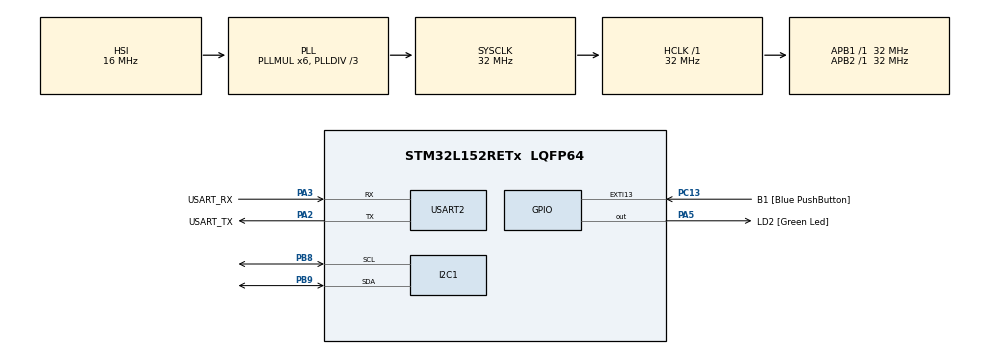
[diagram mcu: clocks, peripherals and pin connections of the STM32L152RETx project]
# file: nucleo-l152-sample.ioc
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Dma.Request0=USART2_RX
Dma.Request1=USART2_TX
Dma.USART2_RX.0.Direction=DMA_PERIPH_TO_MEMORY
Dma.USART2_RX.0.Instance=DMA1_Channel6
Dma.USART2_RX.0.MemDataAlignment=DMA_MDATAALIGN_BYTE
Dma.USART2_RX.0.MemInc=DMA_MINC_ENABLE
Dma.USART2_RX.0.Mode=DMA_NORMAL
Dma.USART2_RX.0.PeriphDataAlignment=DMA_PDATAALIGN_BYTE
Dma.USART2_RX.0.PeriphInc=DMA_PINC_DISABLE
Dma.USART2_RX.0.Priority=DMA_PRIORITY_LOW
Dma.USART2_TX.1.Direction=DMA_MEMORY_TO_PERIPH
Dma.USART2_TX.1.Instance=DMA1_Channel7
Dma.USART2_TX.1.MemDataAlignment=DMA_MDATAALIGN_BYTE
Dma.USART2_TX.1.MemInc=DMA_MINC_ENABLE
Dma.USART2_TX.1.Mode=DMA_NORMAL
Dma.USART2_TX.1.PeriphDataAlignment=DMA_PDATAALIGN_BYTE
Dma.USART2_TX.1.PeriphInc=DMA_PINC_DISABLE
Dma.USART2_TX.1.Priority=DMA_PRIORITY_LOW
FREERTOS.Tasks01=defaultTask,0,128,StartDefaultTask,Default,NULL
FREERTOS.configMINIMAL_STACK_SIZE=256
FREERTOS.configTOTAL_HEAP_SIZE=48000
Mcu.Family=STM32L1
Mcu.Name=STM32L152RETx
Mcu.Package=LQFP64
NVIC.DMA1_Channel6_IRQn=true\:5\:0\:false\:false\:true\:true\:false
NVIC.DMA1_Channel7_IRQn=true\:5\:0\:false\:false\:true\:true\:false
NVIC.EXTI15_10_IRQn=true\:5\:0\:false\:false\:true\:true\:true
NVIC.I2C1_ER_IRQn=true\:5\:0\:false\:false\:true\:true\:true
NVIC.I2C1_EV_IRQn=true\:5\:0\:false\:false\:true\:true\:true
NVIC.PriorityGroup=NVIC_PRIORITYGROUP_4
NVIC.TIM11_IRQn=true\:0\:0\:false\:false\:true\:false\:false
NVIC.TimeBase=TIM11_IRQn
NVIC.TimeBaseIP=TIM11
NVIC.USART2_IRQn=true\:5\:0\:false\:false\:true\:true\:true
PA13.GPIO_Label=TMS
PA13.Mode=Serial_Wire
PA13.Signal=SYS_JTMS-SWDIO
PA14.GPIO_Label=TCK
PA14.Mode=Serial_Wire
PA14.Signal=SYS_JTCK-SWCLK
PA2.GPIO_Label=USART_TX
PA2.Mode=Asynchronous
PA2.Signal=USART2_TX
PA3.GPIO_Label=USART_RX
PA3.Mode=Asynchronous
PA3.Signal=USART2_RX
PA5.GPIO_Label=LD2 [Green Led]
PA5.Signal=GPIO_Output
PB3.GPIO_Label=SWO
PB3.Signal=SYS_JTDO-TRACESWO
PB8.Mode=I2C
PB8.Signal=I2C1_SCL
PB9.Mode=I2C
PB9.Signal=I2C1_SDA
PC13-WKUP2.GPIO_Label=B1 [Blue PushButton]
PC13-WKUP2.Signal=GPXTI13
PC14-OSC32_IN.Mode=LSE-External-Oscillator
PC14-OSC32_IN.Signal=RCC_OSC32_IN
PC15-OSC32_OUT.Mode=LSE-External-Oscillator
PC15-OSC32_OUT.Signal=RCC_OSC32_OUT
PH0-OSC_IN.Mode=HSE-External-Clock-Source
PH0-OSC_IN.Signal=RCC_OSC_IN
PH1-OSC_OUT.Signal=RCC_OSC_OUT
ProjectManager.HeapSize=0x200
ProjectManager.StackSize=0x400
ProjectManager.TargetToolchain=SW4STM32
RCC.48MHZClocksFreq_Value=48000000
RCC.AHBFreq_Value=32000000
RCC.APB1Freq_Value=32000000
RCC.APB1TimFreq_Value=32000000
RCC.APB2Freq_Value=32000000
RCC.APB2TimFreq_Value=32000000
RCC.HCLKFreq_Value=32000000
RCC.HSE_VALUE=8000000
RCC.HSI_VALUE=16000000
RCC.MSI_VALUE=2097000
RCC.PLLDIV=RCC_PLL_DIV3
RCC.PLLMUL=RCC_PLL_MUL6
RCC.RTCClockSelectionVirtual=RCC_RTCCLKSOURCE_LSE
RCC.SYSCLKFreq_VALUE=32000000
RCC.SYSCLKSource=RCC_SYSCLKSOURCE_PLLCLK
RCC.USBOutput=48000000
RCC.VCOOutputFreq_Value=96000000
USART2.VirtualMode=VM_ASYNC
VP_FREERTOS_VS_ENABLE.Mode=Enabled
VP_SYS_VS_tim11.Mode=TIM11
board=NUCLEO-L152RE

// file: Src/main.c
/* USER CODE BEGIN Header */
/**
  ******************************************************************************
  * @file           : main.c
  * @brief          : Main program body
  ******************************************************************************
  * This notice applies to any and all portions of this file
  * that are not between comment pairs USER CODE BEGIN and
  * USER CODE END. Other portions of this file, whether
  * inserted by the user or by software development tools
  * are owned by their respective copyright owners.
  *
  * Copyright (c) 2019 STMicroelectronics International N.V.
  * All rights reserved.
  *
  * Redistribution and use in source and binary forms, with or without
  * modification, are permitted, provided that the following conditions are met:
  *
  * 1. Redistribution of source code must retain the above copyright notice,
  *    this list of conditions and the following disclaimer.
  * 2. Redistributions in binary form must reproduce the above copyright notice,
  *    this list of conditions and the following disclaimer in the documentation
  *    and/or other materials provided with the distribution.
  * 3. Neither the name of STMicroelectronics nor the names of other
  *    contributors to this software may be used to endorse or promote products
  *    derived from this software without specific written permission.
  * 4. This software, including modifications and/or derivative works of this
  *    software, must execute solely and exclusively on microcontroller or
  *    microprocessor devices manufactured by or for STMicroelectronics.
  * 5. Redistribution and use of this software other than as permitted under
  *    this license is void and will automatically terminate your rights under
  *    this license.
  *
  * THIS SOFTWARE IS PROVIDED BY STMICROELECTRONICS AND CONTRIBUTORS "AS IS"
  * AND ANY EXPRESS, IMPLIED OR STATUTORY WARRANTIES, INCLUDING, BUT NOT
  * LIMITED TO, THE IMPLIED WARRANTIES OF MERCHANTABILITY, FITNESS FOR A
  * PARTICULAR PURPOSE AND NON-INFRINGEMENT OF THIRD PARTY INTELLECTUAL PROPERTY
  * RIGHTS ARE DISCLAIMED TO THE FULLEST EXTENT PERMITTED BY LAW. IN NO EVENT
  * SHALL STMICROELECTRONICS OR CONTRIBUTORS BE LIABLE FOR ANY DIRECT, INDIRECT,
  * INCIDENTAL, SPECIAL, EXEMPLARY, OR CONSEQUENTIAL DAMAGES (INCLUDING, BUT NOT
  * LIMITED TO, PROCUREMENT OF SUBSTITUTE GOODS OR SERVICES; LOSS OF USE, DATA,
  * OR PROFITS; OR BUSINESS INTERRUPTION) HOWEVER CAUSED AND ON ANY THEORY OF
  * LIABILITY, WHETHER IN CONTRACT, STRICT LIABILITY, OR TORT (INCLUDING
  * NEGLIGENCE OR OTHERWISE) ARISING IN ANY WAY OUT OF THE USE OF THIS SOFTWARE,
  * EVEN IF ADVISED OF THE POSSIBILITY OF SUCH DAMAGE.
  *
  ******************************************************************************
  */
/* USER CODE END Header */

#include "main.h"
#include "cmsis_os.h"

/* USER CODE BEGIN Includes */
#include "murasaki_platform.hpp"
#include "murasaki_platform.hpp"
/* USER CODE END Includes */

I2C_HandleTypeDef hi2c1;

UART_HandleTypeDef huart2;
DMA_HandleTypeDef hdma_usart2_rx;
DMA_HandleTypeDef hdma_usart2_tx;

osThreadId defaultTaskHandle;

void SystemClock_Config(void);
static void MX_GPIO_Init(void);
static void MX_DMA_Init(void);
static void MX_USART2_UART_Init(void);
static void MX_I2C1_Init(void);
void StartDefaultTask(void const * argument);

int main(void)
{

  /* MCU Configuration--------------------------------------------------------*/

  /* Reset of all peripherals, Initializes the Flash interface and the Systick. */
  HAL_Init();

  /* Configure the system clock */
  SystemClock_Config();

  /* Initialize all configured peripherals */
  MX_GPIO_Init();
  MX_DMA_Init();
  MX_USART2_UART_Init();
  MX_I2C1_Init();

  /* Create the thread(s) */
  /* definition and creation of defaultTask */
  osThreadDef(defaultTask, StartDefaultTask, osPriorityNormal, 0, 128);
  defaultTaskHandle = osThreadCreate(osThread(defaultTask), NULL);

  /* Start scheduler */
  osKernelStart();

  /* We should never get here as control is now taken by the scheduler */

  /* Infinite loop */
  while (1)
  {

  }
}

void SystemClock_Config(void)
{
  RCC_OscInitTypeDef RCC_OscInitStruct = {0};
  RCC_ClkInitTypeDef RCC_ClkInitStruct = {0};

  /**Configure the main internal regulator output voltage
  */
  __HAL_PWR_VOLTAGESCALING_CONFIG(PWR_REGULATOR_VOLTAGE_SCALE1);
  /**Initializes the CPU, AHB and APB busses clocks
  */
  RCC_OscInitStruct.OscillatorType = RCC_OSCILLATORTYPE_HSI;
  RCC_OscInitStruct.HSIState = RCC_HSI_ON;
  RCC_OscInitStruct.HSICalibrationValue = RCC_HSICALIBRATION_DEFAULT;
  RCC_OscInitStruct.PLL.PLLState = RCC_PLL_ON;
  RCC_OscInitStruct.PLL.PLLSource = RCC_PLLSOURCE_HSI;
  RCC_OscInitStruct.PLL.PLLMUL = RCC_PLL_MUL6;
  RCC_OscInitStruct.PLL.PLLDIV = RCC_PLL_DIV3;
  if (HAL_RCC_OscConfig(&RCC_OscInitStruct) != HAL_OK)
  {
    Error_Handler();
  }
  /**Initializes the CPU, AHB and APB busses clocks
  */
  RCC_ClkInitStruct.ClockType = RCC_CLOCKTYPE_HCLK|RCC_CLOCKTYPE_SYSCLK
                              |RCC_CLOCKTYPE_PCLK1|RCC_CLOCKTYPE_PCLK2;
  RCC_ClkInitStruct.SYSCLKSource = RCC_SYSCLKSOURCE_PLLCLK;
  RCC_ClkInitStruct.AHBCLKDivider = RCC_SYSCLK_DIV1;
  RCC_ClkInitStruct.APB1CLKDivider = RCC_HCLK_DIV1;
  RCC_ClkInitStruct.APB2CLKDivider = RCC_HCLK_DIV1;

  if (HAL_RCC_ClockConfig(&RCC_ClkInitStruct, FLASH_LATENCY_1) != HAL_OK)
  {
    Error_Handler();
  }
}

static void MX_I2C1_Init(void)
{

  hi2c1.Instance = I2C1;
  hi2c1.Init.ClockSpeed = 100000;
  hi2c1.Init.DutyCycle = I2C_DUTYCYCLE_2;
  hi2c1.Init.OwnAddress1 = 0;
  hi2c1.Init.AddressingMode = I2C_ADDRESSINGMODE_7BIT;
  hi2c1.Init.DualAddressMode = I2C_DUALADDRESS_DISABLE;
  hi2c1.Init.OwnAddress2 = 0;
  hi2c1.Init.GeneralCallMode = I2C_GENERALCALL_DISABLE;
  hi2c1.Init.NoStretchMode = I2C_NOSTRETCH_DISABLE;
  if (HAL_I2C_Init(&hi2c1) != HAL_OK)
  {
    Error_Handler();
  }

}

static void MX_USART2_UART_Init(void)
{

  huart2.Instance = USART2;
  huart2.Init.BaudRate = 115200;
  huart2.Init.WordLength = UART_WORDLENGTH_8B;
  huart2.Init.StopBits = UART_STOPBITS_1;
  huart2.Init.Parity = UART_PARITY_NONE;
  huart2.Init.Mode = UART_MODE_TX_RX;
  huart2.Init.HwFlowCtl = UART_HWCONTROL_NONE;
  huart2.Init.OverSampling = UART_OVERSAMPLING_16;
  if (HAL_UART_Init(&huart2) != HAL_OK)
  {
    Error_Handler();
  }

}

static void MX_DMA_Init(void)
{
  /* DMA controller clock enable */
  __HAL_RCC_DMA1_CLK_ENABLE();

  /* DMA interrupt init */
  /* DMA1_Channel6_IRQn interrupt configuration */
  HAL_NVIC_SetPriority(DMA1_Channel6_IRQn, 5, 0);
  HAL_NVIC_EnableIRQ(DMA1_Channel6_IRQn);
  /* DMA1_Channel7_IRQn interrupt configuration */
  HAL_NVIC_SetPriority(DMA1_Channel7_IRQn, 5, 0);
  HAL_NVIC_EnableIRQ(DMA1_Channel7_IRQn);

}

static void MX_GPIO_Init(void)
{
  GPIO_InitTypeDef GPIO_InitStruct = {0};

  /* GPIO Ports Clock Enable */
  __HAL_RCC_GPIOC_CLK_ENABLE();
  __HAL_RCC_GPIOH_CLK_ENABLE();
  __HAL_RCC_GPIOA_CLK_ENABLE();
  __HAL_RCC_GPIOB_CLK_ENABLE();

  /*Configure GPIO pin Output Level */
  HAL_GPIO_WritePin(LD2_GPIO_Port, LD2_Pin, GPIO_PIN_RESET);

  /*Configure GPIO pin : B1_Pin */
  GPIO_InitStruct.Pin = B1_Pin;
  GPIO_InitStruct.Mode = GPIO_MODE_IT_RISING;
  GPIO_InitStruct.Pull = GPIO_NOPULL;
  HAL_GPIO_Init(B1_GPIO_Port, &GPIO_InitStruct);

  /*Configure GPIO pin : LD2_Pin */
  GPIO_InitStruct.Pin = LD2_Pin;
  GPIO_InitStruct.Mode = GPIO_MODE_OUTPUT_PP;
  GPIO_InitStruct.Pull = GPIO_NOPULL;
  GPIO_InitStruct.Speed = GPIO_SPEED_FREQ_LOW;
  HAL_GPIO_Init(LD2_GPIO_Port, &GPIO_InitStruct);

  /* EXTI interrupt init*/
  HAL_NVIC_SetPriority(EXTI15_10_IRQn, 5, 0);
  HAL_NVIC_EnableIRQ(EXTI15_10_IRQn);

}

void StartDefaultTask(void const * argument)
{

  /* USER CODE BEGIN 5 */
  InitPlatform();
  ExecPlatform();
    InitPlatform();
    ExecPlatform();
  /* Infinite loop */
  for(;;)
  {
    osDelay(1);
  }
  /* USER CODE END 5 */
}

void HAL_TIM_PeriodElapsedCallback(TIM_HandleTypeDef *htim)
{
  if (htim->Instance == TIM11) {
    HAL_IncTick();
  }
}

void Error_Handler(void)
{
}

#ifdef  USE_FULL_ASSERT
/**
  * @brief  Reports the name of the source file and the source line number
  *         where the assert_param error has occurred.
  * @param  file: pointer to the source file name
  * @param  line: assert_param error line source number
  * @retval None
  */
void assert_failed(uint8_t *file, uint32_t line)
{
  /* USER CODE BEGIN 6 */
  /* User can add his own implementation to report the file name and line number,
     tex: printf("Wrong parameters value: file %s on line %d\r\n", file, line) */
    CustomDefaultHandler(file, line);
    CustomAssertFailed(file, line);
  /* USER CODE END 6 */
}
#endif /* USE_FULL_ASSERT */

/************************ (C) COPYRIGHT STMicroelectronics *****END OF FILE****/
